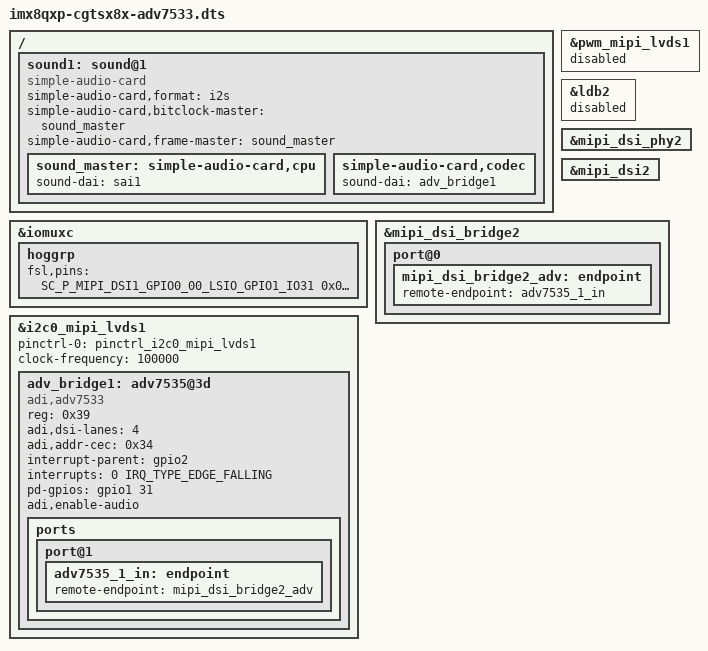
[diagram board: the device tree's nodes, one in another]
/*
 * Copyright 2018 NXP
 * Copyright 2021 congatec GbmH
 *
 * This program is free software; you can redistribute it and/or
 * modify it under the terms of the GNU General Public License
 * as published by the Free Software Foundation; either version 2
 * of the License, or (at your option) any later version.
 *
 * This program is distributed in the hope that it will be useful,
 * but WITHOUT ANY WARRANTY; without even the implied warranty of
 * MERCHANTABILITY or FITNESS FOR A PARTICULAR PURPOSE.  See the
 * GNU General Public License for more details.
 */
/dts-v1/;

#include "imx8qxp-cgtsx8x.dtsi"

/ {	sound1: sound@1 {
		compatible = "simple-audio-card";
		simple-audio-card,format = "i2s";
		simple-audio-card,bitclock-master = <&sound_master>;
		simple-audio-card,frame-master = <&sound_master>;

		sound_master: simple-audio-card,cpu {
			sound-dai = <&sai1>;
		};

		simple-audio-card,codec {
			sound-dai = <&adv_bridge1>;
		};
	};
};

&iomuxc {
	hoggrp {
		fsl,pins = <
			SC_P_MIPI_DSI1_GPIO0_00_LSIO_GPIO1_IO31		0x00000040
		>;
	};
};

&pwm_mipi_lvds1{
        status = "disabled";
};

&ldb2 {
	status = "disabled";
};

&i2c0_mipi_lvds1 {
       #address-cells = <1>;
       #size-cells = <0>;
       pinctrl-names = "default";
       pinctrl-0 = <&pinctrl_i2c0_mipi_lvds1>;
       clock-frequency = <100000>;
       status = "okay";

       adv_bridge1: adv7535@3d {
				compatible = "adi,adv7533";
				reg = <0x39>;
				adi,dsi-lanes = <4>;
				adi,addr-cec = <0x34>;
				interrupt-parent = <&gpio2>;
				interrupts = <0 IRQ_TYPE_EDGE_FALLING>;
				pd-gpios = <&gpio1 31 IRQ_TYPE_LEVEL_LOW>;
				adi,enable-audio;
				status = "okay";
				#sound-dai-cells = <0>;

				ports{
                       #address-cells = <1>;
                       #size-cells = <0>;

                       port@1{
                               adv7535_1_in: endpoint {
                               remote-endpoint = <&mipi_dsi_bridge2_adv>;
							};
                       };
               };
       };
};
&mipi_dsi_phy2{
       status = "okay";
};

&mipi_dsi2 {
       status = "okay";

};

&mipi_dsi_bridge2 {
       status = "okay";

       port@0 {
               mipi_dsi_bridge2_adv: endpoint {
                       remote-endpoint = <&adv7535_1_in>;
               };
       };
};

